# CY8C5888LTI_LP097 register map
File version: 0.1
Registers are 8-bit, read-write, no defined reset value unless marked. A register's access mark holds for its fields unless they carry their own. Offsets are from the block's base; [hi:lo] are bit positions; 'fields as' and 'values as' point back to an identical list.

## QuadDec_R
Base 0x00000000
0x40006406 QuadDec_R_Cnt16_COUNTER 16-bit — Counter value
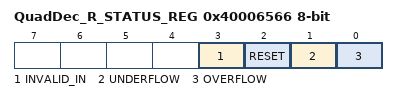
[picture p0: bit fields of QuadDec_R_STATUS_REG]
0x40006566 QuadDec_R_STATUS_REG — Quadrature Decoder Status Register
  [3] INVALID_IN ro — Invalid state transition on the A and B inputs
  [2] RESET ro — Counter Reset due index
  [1] UNDERFLOW ro — Counter underflow
  [0] OVERFLOW ro — Counter overflow

## QuadDec_R_Cnt16
Base 0x00000000; alternate view of QuadDec_R
0x40006406 QuadDec_R_Cnt16_COUNTER 16-bit — UDB.A0 - Current Counter Value
0x40006426 QuadDec_R_Cnt16_PERIOD 16-bit — UDB.D0 - Assigned Period
0x40006436 QuadDec_R_Cnt16_COMPARE 16-bit — UDB.D1 - Assigned Compare Value
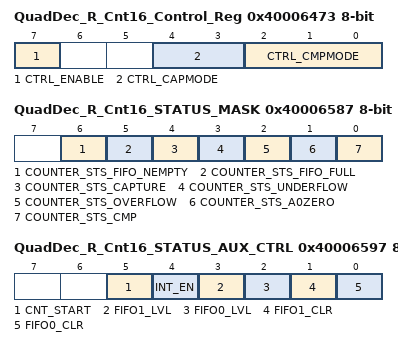
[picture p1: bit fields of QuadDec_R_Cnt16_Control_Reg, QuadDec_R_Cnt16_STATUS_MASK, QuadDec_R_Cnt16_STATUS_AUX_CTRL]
0x40006473 QuadDec_R_Cnt16_Control_Reg — UDB Control Register - Assigned Control Register Value
  [7] CTRL_ENABLE — Enable Counter
  [4:3] CTRL_CAPMODE — Capture mode
  [2:0] CTRL_CMPMODE — Compare mode
0x40006587 QuadDec_R_Cnt16_STATUS_MASK — UDB Status bits Interrupt Mask Enable Register
  [6] COUNTER_STS_FIFO_NEMPTY — FIFO Not Empty Status
  [5] COUNTER_STS_FIFO_FULL — FIFO Full Status
  [4] COUNTER_STS_CAPTURE — Capture Status
  [3] COUNTER_STS_UNDERFLOW — Underflow status
  [2] COUNTER_STS_OVERFLOW — Overflow status
  [1] COUNTER_STS_A0ZERO — A0 Zero ouput status
  [0] COUNTER_STS_CMP — Compare output status
0x40006597 QuadDec_R_Cnt16_STATUS_AUX_CTRL — UDB Auxilliary Control Register
  [5] CNT_START — FIFO0 clear
    0=E_CNT_START0 (Disable counter); 1=E_CNT_START1 (Enable counter)
  [4] INT_EN
    0=E_INT_EN0 (Interrupt disabled); 1=E_INT_EN1 (Interrupt enabled)
  [3] FIFO1_LVL — FIFO level
    0=E_FIFO_LVL_0 (FIFO LVL: input mode: FIFO not full; output mode: FIFO not empty); 1=E_FIFO_LVL_1 (FIFO LVL: input mode: FIFO at least 1/2 empty; output mode: FIFO at least 1/2 full)
  [2] FIFO0_LVL — FIFO level
    values as FIFO1_LVL
  [1] FIFO1_CLR — FIFO1 clear
    0=E_FIFO_CLR_0 (Normal FIFO operation); 1=E_FIFO_CLR_1 (Clear FIFO state)
  [0] FIFO0_CLR — FIFO0 clear
    values as FIFO1_CLR

## QuadDec_L
Base 0x00000000
0x4000640C QuadDec_L_Cnt16_COUNTER 16-bit — Counter value
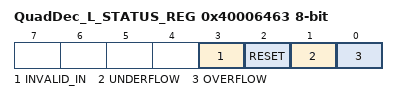
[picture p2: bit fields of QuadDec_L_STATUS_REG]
0x40006463 QuadDec_L_STATUS_REG — Quadrature Decoder Status Register
  [3] INVALID_IN ro — Invalid state transition on the A and B inputs
  [2] RESET ro — Counter Reset due index
  [1] UNDERFLOW ro — Counter underflow
  [0] OVERFLOW ro — Counter overflow

## QuadDec_L_Cnt16
Base 0x00000000; alternate view of QuadDec_L
0x4000640C QuadDec_L_Cnt16_COUNTER 16-bit — UDB.A0 - Current Counter Value
0x4000642C QuadDec_L_Cnt16_PERIOD 16-bit — UDB.D0 - Assigned Period
0x4000643C QuadDec_L_Cnt16_COMPARE 16-bit — UDB.D1 - Assigned Compare Value
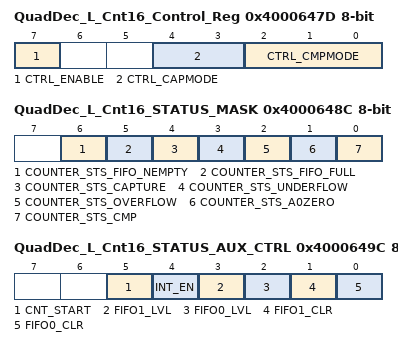
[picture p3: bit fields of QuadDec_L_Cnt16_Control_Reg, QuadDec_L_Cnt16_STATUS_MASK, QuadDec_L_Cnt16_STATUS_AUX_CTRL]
0x4000647D QuadDec_L_Cnt16_Control_Reg — UDB Control Register - Assigned Control Register Value
  [7] CTRL_ENABLE — Enable Counter
  [4:3] CTRL_CAPMODE — Capture mode
  [2:0] CTRL_CMPMODE — Compare mode
0x4000648C QuadDec_L_Cnt16_STATUS_MASK — UDB Status bits Interrupt Mask Enable Register
  [6] COUNTER_STS_FIFO_NEMPTY — FIFO Not Empty Status
  [5] COUNTER_STS_FIFO_FULL — FIFO Full Status
  [4] COUNTER_STS_CAPTURE — Capture Status
  [3] COUNTER_STS_UNDERFLOW — Underflow status
  [2] COUNTER_STS_OVERFLOW — Overflow status
  [1] COUNTER_STS_A0ZERO — A0 Zero ouput status
  [0] COUNTER_STS_CMP — Compare output status
0x4000649C QuadDec_L_Cnt16_STATUS_AUX_CTRL — UDB Auxilliary Control Register
  [5] CNT_START — FIFO0 clear
    0=E_CNT_START0 (Disable counter); 1=E_CNT_START1 (Enable counter)
  [4] INT_EN
    0=E_INT_EN0 (Interrupt disabled); 1=E_INT_EN1 (Interrupt enabled)
  [3] FIFO1_LVL — FIFO level
    0=E_FIFO_LVL_0 (FIFO LVL: input mode: FIFO not full; output mode: FIFO not empty); 1=E_FIFO_LVL_1 (FIFO LVL: input mode: FIFO at least 1/2 empty; output mode: FIFO at least 1/2 full)
  [2] FIFO0_LVL — FIFO level
    values as FIFO1_LVL
  [1] FIFO1_CLR — FIFO1 clear
    0=E_FIFO_CLR_0 (Normal FIFO operation); 1=E_FIFO_CLR_1 (Clear FIFO state)
  [0] FIFO0_CLR — FIFO0 clear
    values as FIFO1_CLR

## S1_Timer
Base 0x00000000
0x4000640E S1_Timer_COUNTER 16-bit — UDB.A0 - Current Down Counter Value
0x4000642E S1_Timer_PERIOD 16-bit — UDB.D0 - Assigned Period
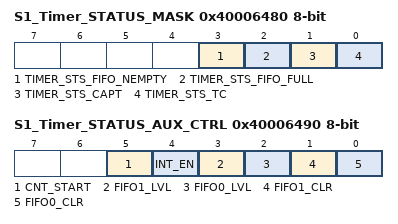
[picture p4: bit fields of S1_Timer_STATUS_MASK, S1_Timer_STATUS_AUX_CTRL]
0x40006480 S1_Timer_STATUS_MASK — UDB Status bits Interrupt Mask Enable Register
  [3] TIMER_STS_FIFO_NEMPTY ro — FIFO Empty status
  [2] TIMER_STS_FIFO_FULL ro — FIFO Full Status
  [1] TIMER_STS_CAPT ro — Enables the Interrupt on Capture
  [0] TIMER_STS_TC ro — Enables the Interrupt on TC
0x40006490 S1_Timer_STATUS_AUX_CTRL — UDB Auxilliary Control Register
  [5] CNT_START — FIFO0 clear
    0=E_CNT_START0 (Disable counter); 1=E_CNT_START1 (Enable counter)
  [4] INT_EN
    0=E_INT_EN0 (Interrupt disabled); 1=E_INT_EN1 (Interrupt enabled)
  [3] FIFO1_LVL — FIFO level
    0=E_FIFO_LVL_0 (FIFO LVL: input mode: FIFO not full; output mode: FIFO not empty); 1=E_FIFO_LVL_1 (FIFO LVL: input mode: FIFO at least 1/2 empty; output mode: FIFO at least 1/2 full)
  [2] FIFO0_LVL — FIFO level
    values as FIFO1_LVL
  [1] FIFO1_CLR — FIFO1 clear
    0=E_FIFO_CLR_0 (Normal FIFO operation); 1=E_FIFO_CLR_1 (Clear FIFO state)
  [0] FIFO0_CLR — FIFO0 clear
    values as FIFO1_CLR

## UART
Base 0x00000000
0x4000644B TX_UART_TX_DATA — TX Data Register
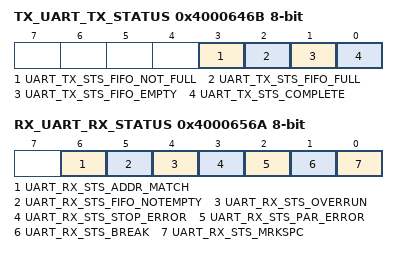
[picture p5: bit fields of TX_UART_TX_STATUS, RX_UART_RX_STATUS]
0x4000646B TX_UART_TX_STATUS — TX status register
  [3] UART_TX_STS_FIFO_NOT_FULL ro, [2] UART_TX_STS_FIFO_FULL ro, [1] UART_TX_STS_FIFO_EMPTY ro, [0] UART_TX_STS_COMPLETE ro
0x4000652B RX_UART_RX_ADDRESS1 — RX Address1 Register
0x4000653B RX_UART_RX_ADDRESS2 — RX Address2 Register
0x4000654B RX_UART_RX_DATA — RX Data Register
0x4000656A RX_UART_RX_STATUS — RX status register
  [6] UART_RX_STS_ADDR_MATCH ro, [5] UART_RX_STS_FIFO_NOTEMPTY ro, [4] UART_RX_STS_OVERRUN ro, [3] UART_RX_STS_STOP_ERROR ro, [2] UART_RX_STS_PAR_ERROR ro, [1] UART_RX_STS_BREAK ro, [0] UART_RX_STS_MRKSPC ro
